CM_ "IMPORT ../../hyundai_kia_generic.dbc";

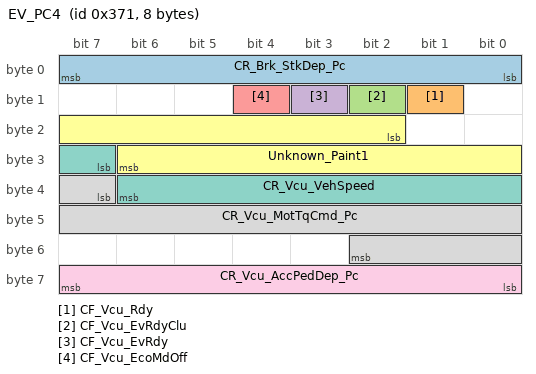
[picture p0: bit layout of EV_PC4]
BO_ 881 EV_PC4: 8 CGW
 SG_ CR_Brk_StkDep_Pc : 0|8@1+ (1,0) [0|0] "%" Vector__XXX
 SG_ CF_Vcu_Rdy : 9|1@1+ (1,0) [0|0] "" Vector__XXX
 SG_ CF_Vcu_EvRdyClu : 10|1@1+ (1,0) [0|0] "" Vector__XXX
 SG_ CF_Vcu_EvRdy : 11|1@1+ (1,0) [0|0] "" Vector__XXX
 SG_ CF_Vcu_EcoMdOff : 12|1@1+ (1,0) [0|0] "" Vector__XXX
 SG_ Unknown_Paint1 : 18|13@1+ (1,0) [0|63] "" XXX
 SG_ CR_Vcu_VehSpeed : 31|8@1+ (0.55,0) [0|100] "kph or mph" Vector__XXX
 SG_ CR_Vcu_MotTqCmd_Pc : 39|12@1- (0.048828125,0) [-100|99.951171875] "%" Vector__XXX
 SG_ CR_Vcu_AccPedDep_Pc : 56|8@1+ (0.3921568627,0) [0|100] "%" XXX
